# WD_TIMER2 register map
Vendor: Texas Instruments
Peripheral module from a debugger description file (folder DRA72x).
Registers are 32-bit, access per field, reset 0x0 unless marked. A register's access mark holds for its fields unless they carry their own. Offsets are as the file gives them; lines under a group give offsets from that group; [hi:lo] are bit positions; {n}, {i} and the like mark numbered series; 'fields as' and 'values as' point back to an identical list; <NAME> marks a mode.

## WD_TIMER2
0x00 WIDR ro reset not defined — IP revision identifier
  [31:0] REV — IP Revision
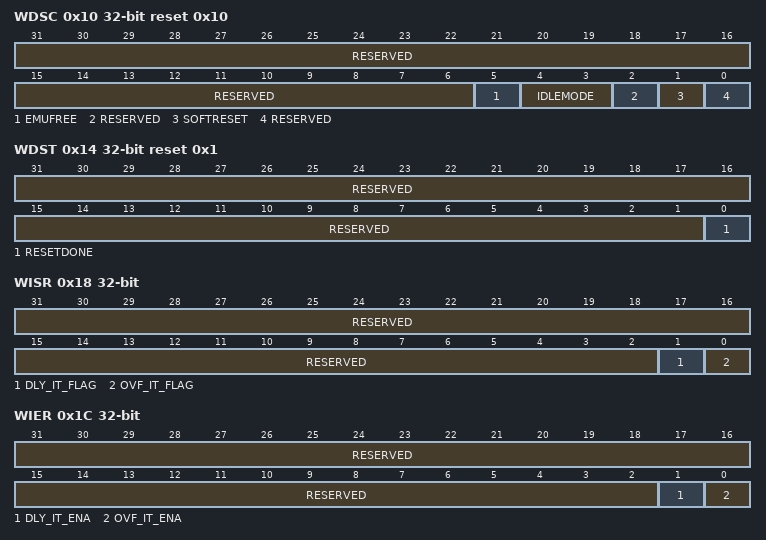
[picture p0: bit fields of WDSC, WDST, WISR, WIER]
0x10 WDSC reset 0x10 — This register controls the various parameters of the L4 interface.
  [31:6] RESERVED ro — Write 0s for future compatibility. Reads return 0.
  [5] EMUFREE rw — Emulation mode
    0=Disabled (Timer counter frozen in emulation); 1=Enabled (Timer counter free-running in emulation)
  [4:3] IDLEMODE rw — Configuration of the local target state management mode. By definition, target can handle read/write transaction as long as it is out of IDLE state.
    0=Force-idle mode: local target IDLE state follows (acknowledges) the system idle requests unconditionally, that is, regardless of the IP module internal requirements. Backup mode, for debug only.; 1=No-idle mode: local target never enters IDLE state. Backup mode, for debug only.; 2=Smart-idle mode: local target IDLE state eventually follows (acknowledges) the system idle requests, depending on the IP module internal requirements. IP module should not generate (IRQ- or DMA-request-related) wake-up events.; 3=Smart-idle wake-up-capable mode: local target IDLE state eventually follows (acknowledges) the system idle requests, depending on the IP module internal requirements. IP module may generate (IRQ- or DMA-request-related) wake-up events when in IDLE state. Mode is relevant only if the appropriate IP moduleswake-up output(s) is (are) implemented.
  [2] RESERVED ro — Write 0s for future compatibility. Reads return 0.
  [1] SOFTRESET rw — Software reset. (Optional)
    0=ResetCompleted (Reset done, no pending action); 0=ResetCompleted (No action); 1=ResetOngoing (Initiate software reset.); 1=ResetOngoing (Reset (software or other) ongoing)
  [0] RESERVED ro — Write 0s for future compatibility. Reads return 0.
0x14 WDST ro reset 0x1 — This register provides status information about the module.
  [31:1] RESERVED — Reads return 0.
  [0] RESETDONE — Internal module reset monitoring
    0=Ongoing (Internal module reset is ongoing.); 1=ResetDone (Reset completed)
0x18 WISR access not given — This register shows which interrupt events are pending inside the module.
  [31:2] RESERVED ro — Reads return 0.
  [1] DLY_IT_FLAG — Pending delay interrupt status. (access RW W1toClr)
    0=Read_0 (No delay interrupt pending); 0=Read_0 (Status unchanged); 1=Write_1 (Status bit cleared); 1=Write_1 (Delay interrupt pending)
  [0] OVF_IT_FLAG — Pending overflow interrupt status. (access RW W1toClr)
    0=Read_0 (No overflow interrupt pending); 0=Read_0 (Status unchanged); 1=Write_1 (Status bit cleared); 1=Write_1 (Overflow interrupt pending)
0x1C WIER — This register controls (enable/disable) the interrupt events.
  [31:2] RESERVED ro — Reads return 0.
  [1] DLY_IT_ENA rw — Delay interrupt enable/disable
    0=Disable delay interrupt; 1=Enable delay interrupt
  [0] OVF_IT_ENA rw — Overflow interrupt enable/disable
    0=Disabled (Disable overflow interrupt.); 1=Enabled (Enable overflow interrupt.)
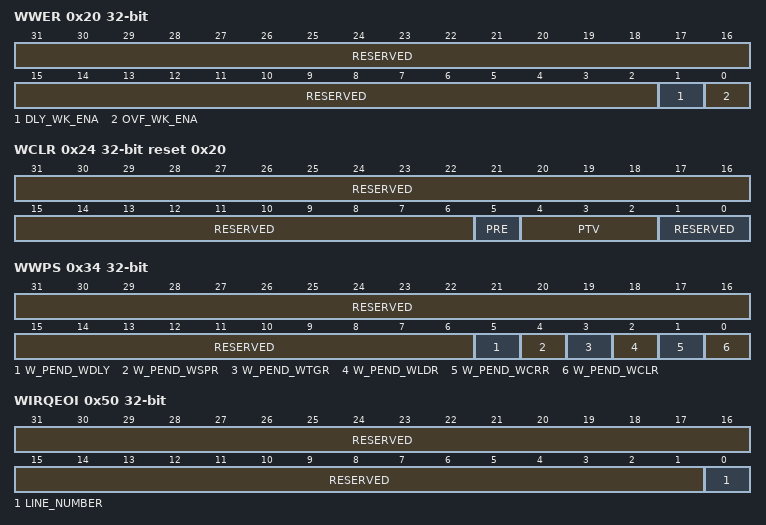
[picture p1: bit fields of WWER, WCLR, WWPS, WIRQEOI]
0x20 WWER — This register controls (enable/disable) the wake-up events.
  [31:2] RESERVED ro — Write 0s for future compatibility. Reads return 0.
  [1] DLY_WK_ENA rw — Delay wake-up enable
    0=Disable delay wakeup; 1=Enable delay wakeup
  [0] OVF_WK_ENA rw — Overflow wake-up enable
    0=Disabled (Disable overflow wakeup.); 1=Enabled (Enable overflow wakeup.)
0x24 WCLR reset 0x20 — This register controls the prescaler stage of the counter.
  [31:6] RESERVED ro — Reads return 0.
  [5] PRE rw — Prescaler enable/disable configuration
    0=Disabled (Prescaler disabled); 1=Enabled (Prescaler enabled)
  [4:2] PTV rw — Prescaler value The timer counter is prescaled with the value: 2. Example: PTV = 3 -&gt; counter increases value if started after 8 functional clock periods. On reset, it is loaded from PI_PTV_RESET_VALUE input port.
  [1:0] RESERVED ro — Write 0s for future compatibility. Reads return 0.
0x28 WCRR rw — This register holds the value of the internal counter.
  [31:0] TIMER_COUNTER — Value of the timer counter register
0x2C WLDR rw — This register holds the timer load value.
  [31:0] TIMER_LOAD — Value of the timer load register
0x30 WTGR rw — Writing a different value than the one already written in this register does a watchdog counter reload.
  [31:0] TTGR_VALUE — Value of the trigger register
0x34 WWPS ro — This register contains the write posting bits for all writeable functional registers.
  [31:6] RESERVED — Write 0s for future compatibility. Reads return 0.
  [5] W_PEND_WDLY — Write pending for registerWDLY
    0=Ready (No register write pending); 1=Ready (Register write pending)
  [4] W_PEND_WSPR — Write pending for registerWSPR
    values as W_PEND_WDLY
  [3] W_PEND_WTGR — Write pending for registerWTGR
    values as W_PEND_WDLY
  [2] W_PEND_WLDR — Write pending for registerWLDR
    values as W_PEND_WDLY
  [1] W_PEND_WCRR — Write pending for registerWCRR
    values as W_PEND_WDLY
  [0] W_PEND_WCLR — Write pending for registerWCLR
    values as W_PEND_WDLY
0x44 WDLY rw — This register holds the delay value that controls the internal pre-overflow event detection.
  [31:0] WDLY_VALUE — Value of the delay register
0x48 WSPR rw — This register holds the start-stop value that controls the internal start-stop FSM.
  [31:0] WSPR_VALUE — Value of the start-stop register
0x50 WIRQEOI — Software End Of Interrupt
  [31:1] RESERVED ro — Write 0's for future compatibility. Reads return 0.
  [0] LINE_NUMBER rw — EOI for interrupt output line Reads always 0 (no EOI memory)
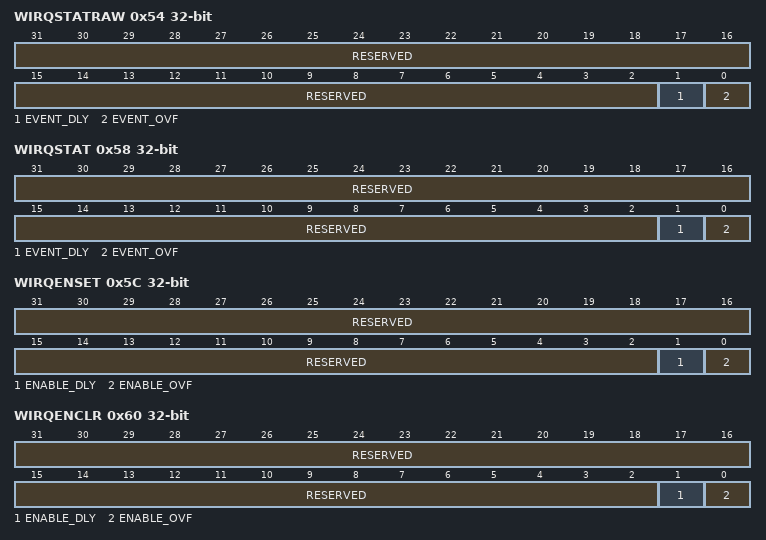
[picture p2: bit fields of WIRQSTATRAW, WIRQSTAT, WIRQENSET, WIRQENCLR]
0x54 WIRQSTATRAW access not given — IRQ unmasked status, status set per-event raw interrupt status vector, line 0. Raw status is set even if event is not enabled. Write 1 to set the (raw) status, mostly for debug.
  [31:2] RESERVED ro — Write 0s for future compatibility. Reads return 0.
  [1] EVENT_DLY — Settable raw status for delay event (access RW W1toSet)
    0=Read_0 (No event pending); 0=Read_0 (No action); 1=Write_1 (Set event (debug)); 1=Write_1 (Event pending)
  [0] EVENT_OVF — Settable raw status for overflow event (access RW W1toSet)
    values as EVENT_DLY
0x58 WIRQSTAT access not given — IRQ masked status, status clear per-event enabled interrupt status vector, line 0. Enabled status is not set unless event is enabled. Write 1 to clear the status after interrupt has been serviced (raw status gets cleared, that is, even if not enabled).
  [31:2] RESERVED ro — Write 0s for future compatibility. Reads return 0.
  [1] EVENT_DLY — Clearable, enabled status for delay event (access RW W1toClr)
    0=Read_0 (No (enabled) event pending); 0=Read_0 (No action); 1=Write_1 (Clear (raw) event); 1=Write_1 (Event pending)
  [0] EVENT_OVF — Clearable, enabled status for overflow event (access RW W1toClr)
    values as EVENT_DLY
0x5C WIRQENSET access not given — IRQ enable set per-event interrupt enable bit vector, line 0. Write 1 to set (enable interrupt). Readout equal to corresponding _CLR register.
  [31:2] RESERVED ro — Write 0s for future compatibility. Reads return 0.
  [1] ENABLE_DLY — Enable for delay event (access RW W1toSet)
    0=Read_0 (Interrupt disabled (masked)); 0=Read_0 (No action); 1=Read_1 (Enable interrupt.); 1=Read_1 (Interrupt enabled)
  [0] ENABLE_OVF — Enable for overflow event (access RW W1toSet)
    values as ENABLE_DLY
0x60 WIRQENCLR access not given — IRQ enable clear per-event interrupt enable bit vector, line 0. Write 1 to clear (disable interrupt). Readout equal to corresponding _SET register.
  [31:2] RESERVED ro — Write 0s for future compatibility. Reads return 0.
  [1] ENABLE_DLY — Enable for delay event (access RW W1toClr)
    0=Read_0 (Interrupt disabled (masked)); 0=Read_0 (No action); 1=Read_1 (Disable interrupt.); 1=Read_1 (Interrupt enabled)
  [0] ENABLE_OVF — Enable for overflow event (access RW W1toClr)
    values as ENABLE_DLY
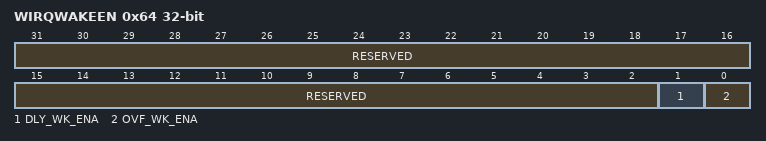
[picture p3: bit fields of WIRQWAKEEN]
0x64 WIRQWAKEEN — This register controls (enable/disable) the wake-up events.
  [31:2] RESERVED ro — Write 0s for future compatibility. Reads return 0.
  [1] DLY_WK_ENA rw — Enable delay wake-up
    0=Disable delay wakeup; 1=Enable delay wakeup
  [0] OVF_WK_ENA rw — Enable overflow wakeup
    0=Disabled (Disable overflow wakeup); 1=Enabled (Enable overflow wakeup)
